# STM32H747_CM4 register map
File version: 2.4
CPU: CM4 r0p1, little endian, MPU, FPU, 4 interrupt priority bits
Registers are 32-bit, read-write, reset 0x0 unless marked. A register's access mark holds for its fields unless they carry their own. Offsets are from the block's base; [hi:lo] are bit positions; {n}, {i} and the like mark numbered series; 'fields as' and 'values as' point back to an identical list.

## RAMECC2 — ECC controller is associated to each RAM area
Base 0x48023000
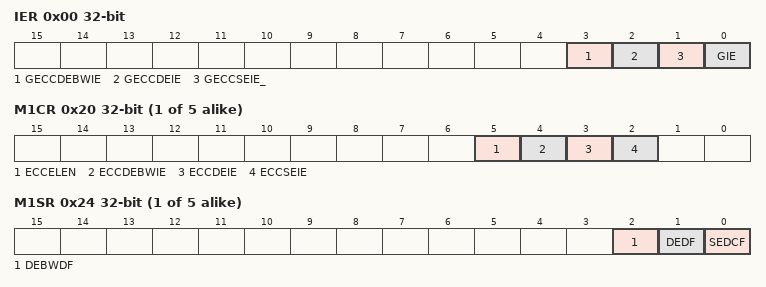
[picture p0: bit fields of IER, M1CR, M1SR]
0x00 IER — RAMECC interrupt enable register
  [3] GECCDEBWIE — Global ECC double error on byte write (BW) interrupt enable
  [2] GECCDEIE — Global ECC double error interrupt enable
  [1] GECCSEIE_ — Global ECC single error interrupt enable
  [0] GIE — Global interrupt enable
{0x0+0x20*i} M{i}CR (i=1..5) — RAMECC monitor x configuration register
  [5] ECCELEN — ECC error latching enable
  [4] ECCDEBWIE — ECC double error on byte write (BW) interrupt enable
  [3] ECCDEIE — ECC double error interrupt enable
  [2] ECCSEIE — ECC single error interrupt enable
{0x4+0x20*i} M{i}SR (i=1..5) — RAMECC monitor x status register
  [2] DEBWDF — ECC double error on byte write (BW) detected flag
  [1] DEDF — ECC double error detected flag
  [0] SEDCF — ECC single error detected and corrected flag
{0x8+0x20*i} M{i}FAR ro (i=1..4) — RAMECC monitor x failing address register
  [31:0] FADD — ECC error failing address
{0xC+0x20*i} M{i}FDRL ro (i=1..5) — RAMECC monitor x failing data low register
  [31:0] FDATAL — Failing data low
0x30 M1FDRH ro — RAMECC monitor x failing data high register
  [31:0] FDATAH — Failing data high (64-bit memory)
0x34 M1FECR — RAMECC monitor x failing ECC error code register
  [31:0] FEC — Failing error code
0x50 M2FDRH — RAMECC monitor x failing data high register
  [31:0] FDATAH — Failing data high (64-bit memory)
0x58 M2FECR — RAMECC monitor x failing ECC error code register
  [31:0] FEC — Failing error code
0x70 M3FDRH ro — RAMECC monitor x failing data high register
  [31:0] FDATAH — Failing data high (64-bit memory)
0x7C M3FECR ro — RAMECC monitor x failing ECC error code register
  [31:0] FEC — Failing error code
0x90 M4FDRH ro — RAMECC monitor x failing data high register
  [31:0] FDATAH — Failing data high (64-bit memory)
0x90 M4FECR ro (alternate view of M4FDRH) — RAMECC monitor x failing ECC error code register
  [31:0] FEC — Failing error code
0xA8 M5FAR — RAMECC monitor x failing address register
  [31:0] FADD — ECC error failing address
0xB0 M5FDRH ro — RAMECC monitor x failing data high register
  [31:0] FEC — Failing error code
0xB4 M5FECR ro — RAMECC monitor x failing ECC error code register
  [31:0] FEC — Failing error code

## RAMECC3 — ECC controller is associated to each RAM area
Base 0x58027000
Registers as RAMECC2, without M{n}CR (n=3..5), M{n}SR (n=3..5), M{n}FAR (n=3..5), M{n}FDRL (n=3..5), M{n}FDRH (n=3..5), M{n}FECR (n=3..5).

## ART — accelerator - control register (ART_CTR)
Base 0x40024400
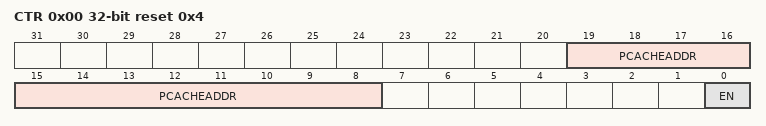
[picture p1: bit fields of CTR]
0x00 CTR reset 0x4 — control register
  [19:8] PCACHEADDR — Cacheable page index
  [0] EN — Cache enable

## DBGMCU — Microcontroller Debug Unit
Base 0x5C001000
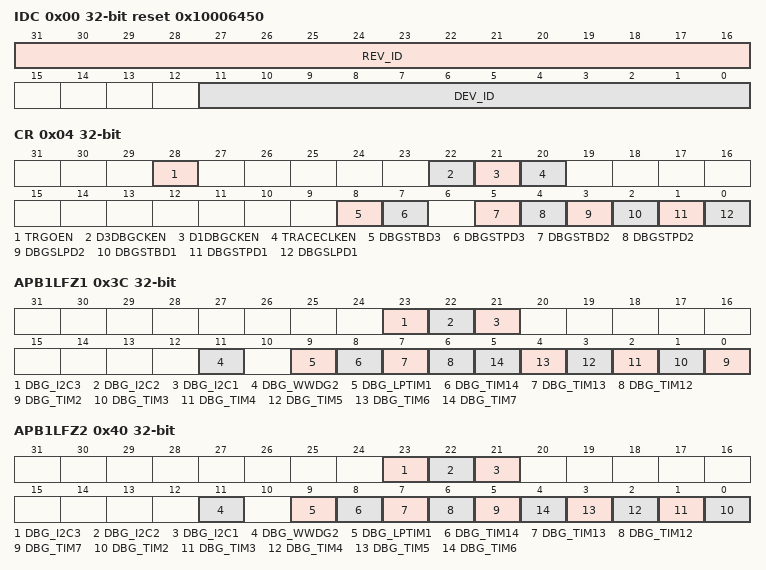
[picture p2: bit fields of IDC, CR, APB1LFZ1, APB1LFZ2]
0x00 IDC ro reset 0x10006450 — DBGMCU Identity Code Register
  [31:16] REV_ID — Revision
  [11:0] DEV_ID — Device ID
0x04 CR — DBGMCU Configuration Register
  [28] TRGOEN — External trigger output enable
  [22] D3DBGCKEN — D3 debug clock enable
  [21] D1DBGCKEN — D1 debug clock enable
  [20] TRACECLKEN — Trace port clock enable
  [8] DBGSTBD3 — Allow debug in D3 Standby mode
  [7] DBGSTPD3 — Allow debug in D3 Stop mode
  [5] DBGSTBD2 — Allow D2 domain debug in Standby mode
  [4] DBGSTPD2 — Allow D2 domain debug in Stop mode
  [3] DBGSLPD2 — Allow D2 domain debug in Sleep mode
  [2] DBGSTBD1 — Allow D1 domain debug in Standby mode
  [1] DBGSTPD1 — Allow D1 domain debug in Stop mode
  [0] DBGSLPD1 — Allow D1 domain debug in Sleep mode
0x34 APB3FZ1 — DBGMCU APB3 peripheral freeze register CPU1
  [6] WWDG1 — WWDG1 stop in debug
0x38 APB3FZ2 — DBGMCU APB3 peripheral freeze register CPU2
  [6] WWDG1 — WWDG1 stop in debug
0x3C APB1LFZ1 — DBGMCU APB1L peripheral freeze register
  [23] DBG_I2C3 — I2C3 SMBUS timeout stop in debug
  [22] DBG_I2C2 — I2C2 SMBUS timeout stop in debug
  [21] DBG_I2C1 — I2C1 SMBUS timeout stop in debug
  [11] DBG_WWDG2 — WWDG2 stop in debug
  [9] DBG_LPTIM1 — LPTIM1 stop in debug
  [8] DBG_TIM14 — TIM14 stop in debug
  [7] DBG_TIM13 — TIM13 stop in debug
  [6] DBG_TIM12 — TIM12 stop in debug
  [n-2] DBG_TIM{n} (n=2..7) — TIM{n} stop in debug
0x40 APB1LFZ2 — DBGMCU APB1L peripheral freeze register CPU2
  [23] DBG_I2C3 — I2C3 SMBUS timeout stop in debug
  [22] DBG_I2C2 — I2C2 SMBUS timeout stop in debug
  [21] DBG_I2C1 — I2C1 SMBUS timeout stop in debug
  [11] DBG_WWDG2 — WWDG2 stop in debug
  [9] DBG_LPTIM1 — LPTIM1 stop in debug
  [8] DBG_TIM14 — TIM14 stop in debug
  [7] DBG_TIM13 — TIM13 stop in debug
  [6] DBG_TIM12 — TIM12 stop in debug
  [5] DBG_TIM7 — TIM4 stop in debug
  [n-2] DBG_TIM{n} (n=2..6) — TIM{n} stop in debug
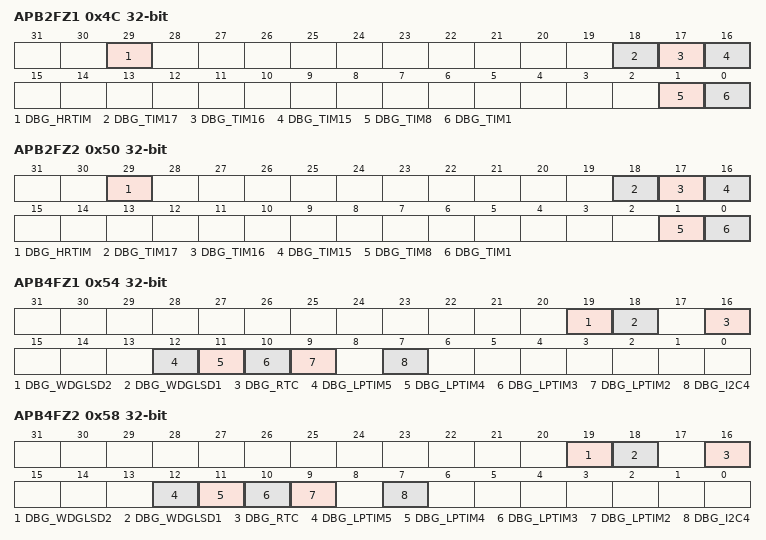
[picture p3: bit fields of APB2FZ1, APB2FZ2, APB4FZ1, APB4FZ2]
0x4C APB2FZ1 — DBGMCU APB2 peripheral freeze register
  [29] DBG_HRTIM — HRTIM stop in debug
  [18] DBG_TIM17 — TIM17 stop in debug
  [17] DBG_TIM16 — TIM16 stop in debug
  [16] DBG_TIM15 — TIM15 stop in debug
  [1] DBG_TIM8 — TIM8 stop in debug
  [0] DBG_TIM1 — TIM1 stop in debug
0x50 APB2FZ2 — DBGMCU APB2 peripheral freeze register CPU2
  fields as APB2FZ1
0x54 APB4FZ1 — DBGMCU APB4 peripheral freeze register
  [19] DBG_WDGLSD2 — Independent watchdog for D2 stop in debug
  [18] DBG_WDGLSD1 — Independent watchdog for D1 stop in debug
  [16] DBG_RTC — RTC stop in debug
  [12] DBG_LPTIM5 — LPTIM5 stop in debug
  [11] DBG_LPTIM4 — LPTIM4 stop in debug
  [10] DBG_LPTIM3 — LPTIM2 stop in debug
  [9] DBG_LPTIM2 — LPTIM2 stop in debug
  [7] DBG_I2C4 — I2C4 SMBUS timeout stop in debug
0x58 APB4FZ2 — DBGMCU APB4 peripheral freeze register CPU2
  [19] DBG_WDGLSD2 — LS watchdog for D2 stop in debug
  [18] DBG_WDGLSD1 — LS watchdog for D1 stop in debug
  [16] DBG_RTC — RTC stop in debug
  [12] DBG_LPTIM5 — LPTIM5 stop in debug
  [11] DBG_LPTIM4 — LPTIM4 stop in debug
  [10] DBG_LPTIM3 — LPTIM2 stop in debug
  [9] DBG_LPTIM2 — LPTIM2 stop in debug
  [7] DBG_I2C4 — I2C4 SMBUS timeout stop in debug

## Notices in the file
Copyright (c) 2025 STMicroelectronics.
SPDX-License-Identifier: Apache-2.0
Licensed under the Apache License, Version 2.0 (the "License");
you may not use this file except in compliance with the License.
You may obtain a copy of the License at
http://www.apache.org/licenses/LICENSE-2.0
Unless required by applicable law or agreed to in writing, software
distributed under the License is distributed on an "AS IS" BASIS,
WITHOUT WARRANTIES OR CONDITIONS OF ANY KIND, either express or implied.
See the License for the specific language governing permissions and
limitations under the License.
